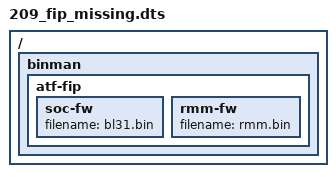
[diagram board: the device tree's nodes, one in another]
// SPDX-License-Identifier: GPL-2.0+
/dts-v1/;

/ {
	#address-cells = <1>;
	#size-cells = <1>;

	binman {
		atf-fip {
			soc-fw {
				filename = "bl31.bin";
			};

			rmm-fw {
				filename = "rmm.bin";
			};
		};
	};
};
